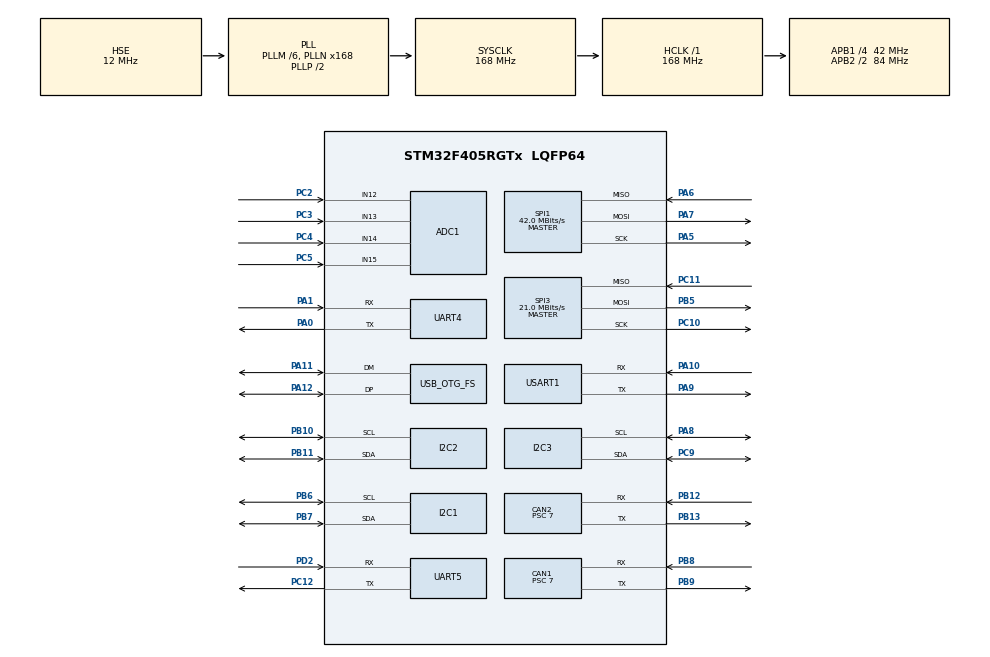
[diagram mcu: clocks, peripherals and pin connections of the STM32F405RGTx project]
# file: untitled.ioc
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ADC1.Channel-0\#ChannelRegularConversion=ADC_CHANNEL_12
ADC1.Channel-15\#ChannelRegularConversion=ADC_CHANNEL_13
ADC1.Channel-16\#ChannelRegularConversion=ADC_CHANNEL_14
ADC1.Channel-17\#ChannelRegularConversion=ADC_CHANNEL_15
ADC1.Channel-18\#ChannelRegularConversion=ADC_CHANNEL_TEMPSENSOR
ADC1.Channel-19\#ChannelRegularConversion=ADC_CHANNEL_VREFINT
ADC1.InjNumberOfConversion=0
ADC1.NbrOfConversion=6
ADC1.NbrOfConversionFlag=1
ADC1.Rank-15\#ChannelRegularConversion=2
ADC1.Rank-16\#ChannelRegularConversion=3
ADC1.Rank-17\#ChannelRegularConversion=4
ADC1.Rank-18\#ChannelRegularConversion=5
ADC1.Rank-19\#ChannelRegularConversion=6
ADC1.SamplingTime-0\#ChannelRegularConversion=ADC_SAMPLETIME_28CYCLES
ADC1.SamplingTime-15\#ChannelRegularConversion=ADC_SAMPLETIME_28CYCLES
ADC1.SamplingTime-16\#ChannelRegularConversion=ADC_SAMPLETIME_28CYCLES
ADC1.SamplingTime-17\#ChannelRegularConversion=ADC_SAMPLETIME_28CYCLES
ADC1.SamplingTime-18\#ChannelRegularConversion=ADC_SAMPLETIME_28CYCLES
ADC1.SamplingTime-19\#ChannelRegularConversion=ADC_SAMPLETIME_28CYCLES
ADC1.master=1
CAN1.AWUM=ENABLE
CAN1.BS1=CAN_BS1_3TQ
CAN1.BS2=CAN_BS2_2TQ
CAN1.CalculateBaudRate=999999
CAN1.CalculateTimeBit=1000
CAN1.CalculateTimeQuantum=166.66666666666669
CAN1.Prescaler=7
CAN1.TXFP=ENABLE
CAN2.AWUM=ENABLE
CAN2.BS1=CAN_BS1_3TQ
CAN2.BS2=CAN_BS2_2TQ
CAN2.CalculateBaudRate=999999
CAN2.CalculateTimeBit=1000
CAN2.CalculateTimeQuantum=166.66666666666669
CAN2.Prescaler=7
CAN2.TXFP=ENABLE
Dma.ADC1.6.Direction=DMA_PERIPH_TO_MEMORY
Dma.ADC1.6.FIFOMode=DMA_FIFOMODE_DISABLE
Dma.ADC1.6.Instance=DMA2_Stream0
Dma.ADC1.6.MemDataAlignment=DMA_MDATAALIGN_HALFWORD
Dma.ADC1.6.MemInc=DMA_MINC_ENABLE
Dma.ADC1.6.Mode=DMA_NORMAL
Dma.ADC1.6.PeriphDataAlignment=DMA_PDATAALIGN_HALFWORD
Dma.ADC1.6.PeriphInc=DMA_PINC_DISABLE
Dma.ADC1.6.Priority=DMA_PRIORITY_LOW
Dma.Request0=USART1_RX
Dma.Request1=USART1_TX
Dma.Request2=UART5_RX
Dma.Request3=UART5_TX
Dma.Request4=UART4_RX
Dma.Request5=UART4_TX
Dma.Request6=ADC1
Dma.UART4_RX.4.Direction=DMA_PERIPH_TO_MEMORY
Dma.UART4_RX.4.FIFOMode=DMA_FIFOMODE_DISABLE
Dma.UART4_RX.4.Instance=DMA1_Stream2
Dma.UART4_RX.4.MemDataAlignment=DMA_MDATAALIGN_BYTE
Dma.UART4_RX.4.MemInc=DMA_MINC_ENABLE
Dma.UART4_RX.4.Mode=DMA_CIRCULAR
Dma.UART4_RX.4.PeriphDataAlignment=DMA_PDATAALIGN_BYTE
Dma.UART4_RX.4.PeriphInc=DMA_PINC_DISABLE
Dma.UART4_RX.4.Priority=DMA_PRIORITY_LOW
Dma.UART4_TX.5.Direction=DMA_MEMORY_TO_PERIPH
Dma.UART4_TX.5.FIFOMode=DMA_FIFOMODE_DISABLE
Dma.UART4_TX.5.Instance=DMA1_Stream4
Dma.UART4_TX.5.MemDataAlignment=DMA_MDATAALIGN_BYTE
Dma.UART4_TX.5.MemInc=DMA_MINC_ENABLE
Dma.UART4_TX.5.Mode=DMA_NORMAL
Dma.UART4_TX.5.PeriphDataAlignment=DMA_PDATAALIGN_BYTE
Dma.UART4_TX.5.PeriphInc=DMA_PINC_DISABLE
Dma.UART4_TX.5.Priority=DMA_PRIORITY_LOW
Dma.UART5_RX.2.Direction=DMA_PERIPH_TO_MEMORY
Dma.UART5_RX.2.FIFOMode=DMA_FIFOMODE_DISABLE
Dma.UART5_RX.2.Instance=DMA1_Stream0
Dma.UART5_RX.2.MemDataAlignment=DMA_MDATAALIGN_BYTE
Dma.UART5_RX.2.MemInc=DMA_MINC_ENABLE
Dma.UART5_RX.2.Mode=DMA_CIRCULAR
Dma.UART5_RX.2.PeriphDataAlignment=DMA_PDATAALIGN_BYTE
Dma.UART5_RX.2.PeriphInc=DMA_PINC_DISABLE
Dma.UART5_RX.2.Priority=DMA_PRIORITY_LOW
Dma.UART5_TX.3.Direction=DMA_MEMORY_TO_PERIPH
Dma.UART5_TX.3.FIFOMode=DMA_FIFOMODE_DISABLE
Dma.UART5_TX.3.Instance=DMA1_Stream7
Dma.UART5_TX.3.MemDataAlignment=DMA_MDATAALIGN_BYTE
Dma.UART5_TX.3.MemInc=DMA_MINC_ENABLE
Dma.UART5_TX.3.Mode=DMA_NORMAL
Dma.UART5_TX.3.PeriphDataAlignment=DMA_PDATAALIGN_BYTE
Dma.UART5_TX.3.PeriphInc=DMA_PINC_DISABLE
Dma.UART5_TX.3.Priority=DMA_PRIORITY_LOW
Dma.USART1_RX.0.Direction=DMA_PERIPH_TO_MEMORY
Dma.USART1_RX.0.FIFOMode=DMA_FIFOMODE_DISABLE
Dma.USART1_RX.0.Instance=DMA2_Stream2
Dma.USART1_RX.0.MemDataAlignment=DMA_MDATAALIGN_BYTE
Dma.USART1_RX.0.MemInc=DMA_MINC_ENABLE
Dma.USART1_RX.0.Mode=DMA_CIRCULAR
Dma.USART1_RX.0.PeriphDataAlignment=DMA_PDATAALIGN_BYTE
Dma.USART1_RX.0.PeriphInc=DMA_PINC_DISABLE
Dma.USART1_RX.0.Priority=DMA_PRIORITY_LOW
Dma.USART1_TX.1.Direction=DMA_MEMORY_TO_PERIPH
Dma.USART1_TX.1.FIFOMode=DMA_FIFOMODE_DISABLE
Dma.USART1_TX.1.Instance=DMA2_Stream7
Dma.USART1_TX.1.MemDataAlignment=DMA_MDATAALIGN_BYTE
Dma.USART1_TX.1.MemInc=DMA_MINC_ENABLE
Dma.USART1_TX.1.Mode=DMA_NORMAL
Dma.USART1_TX.1.PeriphDataAlignment=DMA_PDATAALIGN_BYTE
Dma.USART1_TX.1.PeriphInc=DMA_PINC_DISABLE
Dma.USART1_TX.1.Priority=DMA_PRIORITY_LOW
FREERTOS.Tasks01=defaultTask,24,500,StartDefaultTask,Default,NULL,Dynamic,NULL,NULL
FREERTOS.configENABLE_FPU=1
FREERTOS.configTOTAL_HEAP_SIZE=65535
I2C1.I2C_Mode=I2C_Fast
I2C2.I2C_Mode=I2C_Fast
I2C3.I2C_Mode=I2C_Fast
Mcu.Family=STM32F4
Mcu.Name=STM32F405RGTx
Mcu.Package=LQFP64
NVIC.ADC_IRQn=true\:5\:0\:false\:false\:true\:true\:true\:true\:true
NVIC.CAN1_RX0_IRQn=true\:5\:0\:false\:false\:true\:true\:true\:true\:true
NVIC.CAN1_RX1_IRQn=true\:5\:0\:false\:false\:true\:true\:true\:true\:true
NVIC.CAN1_SCE_IRQn=true\:5\:0\:false\:false\:true\:true\:true\:true\:true
NVIC.CAN1_TX_IRQn=true\:5\:0\:false\:false\:true\:true\:true\:true\:true
NVIC.CAN2_RX0_IRQn=true\:5\:0\:false\:false\:true\:true\:true\:true\:true
NVIC.CAN2_RX1_IRQn=true\:5\:0\:false\:false\:true\:true\:true\:true\:true
NVIC.CAN2_SCE_IRQn=true\:5\:0\:false\:false\:true\:true\:true\:true\:true
NVIC.CAN2_TX_IRQn=true\:5\:0\:false\:false\:true\:true\:true\:true\:true
NVIC.DMA1_Stream0_IRQn=true\:5\:0\:false\:false\:true\:true\:false\:true\:true
NVIC.DMA1_Stream2_IRQn=true\:5\:0\:false\:false\:true\:true\:false\:true\:true
NVIC.DMA1_Stream4_IRQn=true\:5\:0\:false\:false\:true\:true\:false\:true\:true
NVIC.DMA1_Stream7_IRQn=true\:5\:0\:false\:false\:true\:true\:false\:true\:true
NVIC.DMA2_Stream0_IRQn=true\:5\:0\:false\:false\:true\:true\:false\:true\:true
NVIC.DMA2_Stream2_IRQn=true\:5\:0\:false\:false\:true\:true\:false\:true\:true
NVIC.DMA2_Stream7_IRQn=true\:5\:0\:false\:false\:true\:true\:false\:true\:true
NVIC.OTG_FS_IRQn=true\:5\:0\:false\:false\:true\:true\:true\:true\:true
NVIC.PriorityGroup=NVIC_PRIORITYGROUP_4
NVIC.TIM6_DAC_IRQn=true\:15\:0\:false\:false\:true\:false\:false\:true\:true
NVIC.TIM8_TRG_COM_TIM14_IRQn=true\:5\:0\:false\:false\:true\:true\:true\:true\:true
NVIC.TIM8_UP_TIM13_IRQn=true\:5\:0\:false\:false\:true\:true\:true\:true\:true
NVIC.TimeBase=TIM6_DAC_IRQn
NVIC.TimeBaseIP=TIM6
NVIC.UART4_IRQn=true\:5\:0\:false\:false\:true\:true\:true\:true\:true
NVIC.UART5_IRQn=true\:5\:0\:false\:false\:true\:true\:true\:true\:true
NVIC.USART1_IRQn=true\:5\:0\:false\:false\:true\:true\:true\:true\:true
PA0-WKUP.Mode=Asynchronous
PA0-WKUP.Signal=UART4_TX
PA1.Mode=Asynchronous
PA1.Signal=UART4_RX
PA10.Mode=Asynchronous
PA10.Signal=USART1_RX
PA11.Mode=Device_Only
PA11.Signal=USB_OTG_FS_DM
PA12.Mode=Device_Only
PA12.Signal=USB_OTG_FS_DP
PA13.Mode=Serial_Wire
PA13.Signal=SYS_JTMS-SWDIO
PA14.Mode=Serial_Wire
PA14.Signal=SYS_JTCK-SWCLK
PA5.Mode=Full_Duplex_Master
PA5.Signal=SPI1_SCK
PA6.Mode=Full_Duplex_Master
PA6.Signal=SPI1_MISO
PA7.Mode=Full_Duplex_Master
PA7.Signal=SPI1_MOSI
PA8.Mode=I2C
PA8.Signal=I2C3_SCL
PA9.Mode=Asynchronous
PA9.Signal=USART1_TX
PB10.Mode=I2C
PB10.Signal=I2C2_SCL
PB11.Mode=I2C
PB11.Signal=I2C2_SDA
PB12.Mode=CAN_Activate
PB12.Signal=CAN2_RX
PB13.Mode=CAN_Activate
PB13.Signal=CAN2_TX
PB5.Mode=Full_Duplex_Master
PB5.Signal=SPI3_MOSI
PB6.Mode=I2C
PB6.Signal=I2C1_SCL
PB7.Mode=I2C
PB7.Signal=I2C1_SDA
PB8.Mode=CAN_Activate
PB8.Signal=CAN1_RX
PB9.Mode=CAN_Activate
PB9.Signal=CAN1_TX
PC10.Mode=Full_Duplex_Master
PC10.Signal=SPI3_SCK
PC11.Mode=Full_Duplex_Master
PC11.Signal=SPI3_MISO
PC12.Mode=Asynchronous
PC12.Signal=UART5_TX
PC2.Signal=ADCx_IN12
PC3.Signal=ADCx_IN13
PC4.Signal=ADCx_IN14
PC5.Signal=ADCx_IN15
PC9.Mode=I2C
PC9.Signal=I2C3_SDA
PD2.Mode=Asynchronous
PD2.Signal=UART5_RX
PH0-OSC_IN.Mode=HSE-External-Oscillator
PH0-OSC_IN.Signal=RCC_OSC_IN
PH1-OSC_OUT.Mode=HSE-External-Oscillator
PH1-OSC_OUT.Signal=RCC_OSC_OUT
ProjectManager.HeapSize=0x3C00
ProjectManager.StackSize=0x800
ProjectManager.TargetToolchain=STM32CubeIDE
RCC.48MHZClocksFreq_Value=48000000
RCC.AHBFreq_Value=168000000
RCC.APB1CLKDivider=RCC_HCLK_DIV4
RCC.APB1Freq_Value=42000000
RCC.APB1TimFreq_Value=84000000
RCC.APB2CLKDivider=RCC_HCLK_DIV2
RCC.APB2Freq_Value=84000000
RCC.APB2TimFreq_Value=168000000
RCC.CortexFreq_Value=168000000
RCC.HCLKFreq_Value=168000000
RCC.HSE_VALUE=12000000
RCC.HSI_VALUE=16000000
RCC.LSE_VALUE=32768
RCC.PLLM=6
RCC.PLLN=168
RCC.PLLQ=7
RCC.SYSCLKFreq_VALUE=168000000
RCC.SYSCLKSource=RCC_SYSCLKSOURCE_PLLCLK
RCC.VCOOutputFreq_Value=336000000
SH.ADCx_IN12.0=ADC1_IN12,IN12
SH.ADCx_IN13.0=ADC1_IN13,IN13
SH.ADCx_IN14.0=ADC1_IN14,IN14
SH.ADCx_IN15.0=ADC1_IN15,IN15
SPI1.BaudRatePrescaler=SPI_BAUDRATEPRESCALER_2
SPI1.CalculateBaudRate=42.0 MBits/s
SPI1.Direction=SPI_DIRECTION_2LINES
SPI1.Mode=SPI_MODE_MASTER
SPI1.VirtualType=VM_MASTER
SPI3.BaudRatePrescaler=SPI_BAUDRATEPRESCALER_2
SPI3.CalculateBaudRate=21.0 MBits/s
SPI3.Direction=SPI_DIRECTION_2LINES
SPI3.Mode=SPI_MODE_MASTER
SPI3.VirtualType=VM_MASTER
TIM13.Period=9999
TIM13.Prescaler=83
TIM14.Period=9999
TIM14.Prescaler=83
UART4.VirtualMode=Asynchronous
UART5.VirtualMode=Asynchronous
USART1.VirtualMode=VM_ASYNC
USB_DEVICE.CLASS_NAME_FS=CDC
USB_DEVICE.VirtualMode-CDC_FS=Cdc
USB_DEVICE.VirtualModeFS=Cdc_FS
USB_OTG_FS.VirtualMode=Device_Only
VP_ADC1_TempSens_Input.Mode=IN-TempSens
VP_ADC1_Vref_Input.Mode=IN-Vrefint
VP_FREERTOS_VS_CMSIS_V2.Mode=CMSIS_V2
VP_SYS_VS_tim6.Mode=TIM6
VP_TIM13_VS_ClockSourceINT.Mode=Enable_Timer
VP_TIM14_VS_ClockSourceINT.Mode=Enable_Timer
VP_USB_DEVICE_VS_USB_DEVICE_CDC_FS.Mode=CDC_FS
board=custom

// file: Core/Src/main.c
/* USER CODE BEGIN Header */
/**
  ******************************************************************************
  * @file           : main.c
  * @brief          : Main program body
  ******************************************************************************
  * @attention
  *
  * Copyright (c) 2025 STMicroelectronics.
  * All rights reserved.
  *
  * This software is licensed under terms that can be found in the LICENSE file
  * in the root directory of this software component.
  * If no LICENSE file comes with this software, it is provided AS-IS.
  *
  ******************************************************************************
  */
/* USER CODE END Header */
#include "main.h"
#include "cmsis_os.h"
#include "adc.h"
#include "can.h"
#include "dma.h"
#include "i2c.h"
#include "spi.h"
#include "tim.h"
#include "usart.h"
#include "usb_device.h"
#include "gpio.h"

void SystemClock_Config(void);
void MX_FREERTOS_Init(void);

int main(void)
{

  /* MCU Configuration--------------------------------------------------------*/

  /* Reset of all peripherals, Initializes the Flash interface and the Systick. */
  HAL_Init();

  /* Configure the system clock */
  SystemClock_Config();

  /* Initialize all configured peripherals */
  MX_GPIO_Init();
  MX_DMA_Init();
  MX_CAN1_Init();
  MX_CAN2_Init();
  MX_I2C1_Init();
  MX_USART1_UART_Init();
  MX_I2C2_Init();
  MX_TIM14_Init();
  MX_UART5_Init();
  MX_UART4_Init();
  MX_ADC1_Init();
  MX_I2C3_Init();
  MX_SPI1_Init();
  MX_SPI3_Init();
  MX_TIM13_Init();

  /* Init scheduler */
  osKernelInitialize();  /* Call init function for freertos objects (in freertos.c) */
  MX_FREERTOS_Init();

  /* Start scheduler */
  osKernelStart();

  /* We should never get here as control is now taken by the scheduler */
  /* Infinite loop */
  while (1)
  {

  }
}

void SystemClock_Config(void)
{
  RCC_OscInitTypeDef RCC_OscInitStruct = {0};
  RCC_ClkInitTypeDef RCC_ClkInitStruct = {0};

  /** Configure the main internal regulator output voltage
  */
  __HAL_RCC_PWR_CLK_ENABLE();
  __HAL_PWR_VOLTAGESCALING_CONFIG(PWR_REGULATOR_VOLTAGE_SCALE1);

  /** Initializes the RCC Oscillators according to the specified parameters
  * in the RCC_OscInitTypeDef structure.
  */
  RCC_OscInitStruct.OscillatorType = RCC_OSCILLATORTYPE_HSE;
  RCC_OscInitStruct.HSEState = RCC_HSE_ON;
  RCC_OscInitStruct.PLL.PLLState = RCC_PLL_ON;
  RCC_OscInitStruct.PLL.PLLSource = RCC_PLLSOURCE_HSE;
  RCC_OscInitStruct.PLL.PLLM = 6;
  RCC_OscInitStruct.PLL.PLLN = 168;
  RCC_OscInitStruct.PLL.PLLP = RCC_PLLP_DIV2;
  RCC_OscInitStruct.PLL.PLLQ = 7;
  if (HAL_RCC_OscConfig(&RCC_OscInitStruct) != HAL_OK)
  {
    Error_Handler();
  }

  /** Initializes the CPU, AHB and APB buses clocks
  */
  RCC_ClkInitStruct.ClockType = RCC_CLOCKTYPE_HCLK|RCC_CLOCKTYPE_SYSCLK
                              |RCC_CLOCKTYPE_PCLK1|RCC_CLOCKTYPE_PCLK2;
  RCC_ClkInitStruct.SYSCLKSource = RCC_SYSCLKSOURCE_PLLCLK;
  RCC_ClkInitStruct.AHBCLKDivider = RCC_SYSCLK_DIV1;
  RCC_ClkInitStruct.APB1CLKDivider = RCC_HCLK_DIV4;
  RCC_ClkInitStruct.APB2CLKDivider = RCC_HCLK_DIV2;

  if (HAL_RCC_ClockConfig(&RCC_ClkInitStruct, FLASH_LATENCY_5) != HAL_OK)
  {
    Error_Handler();
  }
}

void HAL_TIM_PeriodElapsedCallback(TIM_HandleTypeDef *htim)
{
  if (htim->Instance == TIM6) {
    HAL_IncTick();
  }
}

void Error_Handler(void)
{
  __disable_irq();
  while (1)
  {
  }
}

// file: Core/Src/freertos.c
/* USER CODE BEGIN Header */
/**
  ******************************************************************************
  * File Name          : freertos.c
  * Description        : Code for freertos applications
  ******************************************************************************
  * @attention
  *
  * Copyright (c) 2025 STMicroelectronics.
  * All rights reserved.
  *
  * This software is licensed under terms that can be found in the LICENSE file
  * in the root directory of this software component.
  * If no LICENSE file comes with this software, it is provided AS-IS.
  *
  ******************************************************************************
  */
/* USER CODE END Header */

#include "FreeRTOS.h"
#include "task.h"
#include "main.h"
#include "cmsis_os.h"

/* USER CODE BEGIN Includes */
#include "common_inc.h"
/* USER CODE END Includes */

/* Definitions for defaultTask */
osThreadId_t defaultTaskHandle;
const osThreadAttr_t defaultTask_attributes = {
  .name = "defaultTask",
  .stack_size = 500 * 4,
  .priority = (osPriority_t) osPriorityNormal,
};

void StartDefaultTask(void *argument);

extern void MX_USB_DEVICE_Init(void);
void MX_FREERTOS_Init(void); /* (MISRA C 2004 rule 8.1) */

void MX_FREERTOS_Init(void) {

  /* Create the thread(s) */
  /* creation of defaultTask */
  defaultTaskHandle = osThreadNew(StartDefaultTask, NULL, &defaultTask_attributes);

}

void StartDefaultTask(void *argument)
{
  /* init code for USB_DEVICE */
  MX_USB_DEVICE_Init();
  /* USER CODE BEGIN StartDefaultTask */

  Main();
  vTaskDelete(defaultTaskHandle);

  /* Infinite loop */
  // for(;;)
  // {
  //   osDelay(1);
  // }
  /* USER CODE END StartDefaultTask */
}
